# STM32F051x8 register map
File version: 1.0
Registers are 32-bit, read-write, reset 0x0 unless marked. A register's access mark holds for its fields unless they carry their own. Offsets are from the block's base; [hi:lo] are bit positions; {n}, {i} and the like mark numbered series.

## COMP12_COMMON
Base 0x4001001C; alternate view of COMP
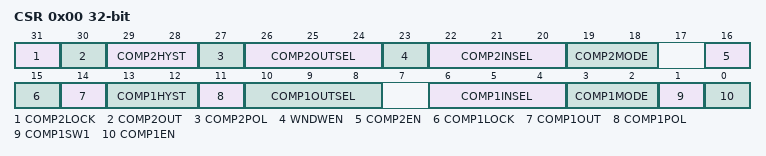
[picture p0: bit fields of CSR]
0x00 CSR — COMP control and status register, used for bits common to several COMP instances
  [31] COMP2LOCK
  [30] COMP2OUT — COMP2 output level
  [29:28] COMP2HYST — COMP2 hysteresis
  [27] COMP2POL — COMP2 output polarity
  [26:24] COMP2OUTSEL — COMP2 output select
  [23] WNDWEN — COMPx window mode. Bit intended to be used with COMP common instance (COMP_Common_TypeDef)
    0=DISABLE (Window mode disable: Comparators 1 and 2 are independent); 1=COMP1_INPUT_PLUS_COMMON (Window mode enable: Comparators instances pair COMP1 and COMP2 have their input plus connected together. The common input is COMP1 input plus (COMP2 input plus is no more accessible).)
  [22:20] COMP2INSEL — COMP2 inverting input select
  [19:18] COMP2MODE — COMP2 power mode
  [16] COMP2EN — COMP2 enable
  [15] COMP1LOCK
  [14] COMP1OUT — COMP1 output level
  [13:12] COMP1HYST — COMP1 hysteresis
    0=NONE (No hysteresis); 1=LOW (Hysteresis level low); 2=MEDIUM (Hysteresis level medium); 3=HIGH (Hysteresis level high)
  [11] COMP1POL — COMP1 output polarity
    0=NONINVERTED (COMP output polarity is not inverted: comparator output is high when the plus (non-inverting) input is at a higher voltage than the minus (inverting) input); 1=INVERTED (COMP output polarity is inverted: comparator output is low when the plus (non-inverting) input is at a lower voltage than the minus (inverting) input)
  [10:8] COMP1OUTSEL — COMP1 output select
    0=NONE (COMP output is not connected to other peripherals (except GPIO and EXTI that are always connected to COMP output)); 1=TIM1_BKIN (COMP output connected to TIM1 break input (BKIN)); 2=TIM1_IC1 (COMP output connected to TIM1 input capture 1); 3=TIM1_OCCLR (COMP output connected to TIM1 OCREF clear); 4=TIM2_IC4 (COMP output connected to TIM2 input capture 4); 5=TIM2_OCCLR (COMP output connected to TIM2 OCREF clear); 6=TIM3_IC1 (COMP output connected to TIM3 input capture 1); 7=TIM3_OCCLR (COMP output connected to TIM3 OCREF clear)
  [6:4] COMP1INSEL — COMP1 inverting input select
    0=MINUS_1_4VREFINT (Comparator input minus connected to 1/4 VrefInt); 1=MINUS_1_2VREFINT (Comparator input minus connected to 1/2 VrefInt); 2=MINUS_3_4VREFINT (Comparator input minus connected to 3/4 VrefInt); 3=VREFINT (Comparator input minus connected to VrefInt); 4=DAC1_CH1 (Comparator input minus connected to DAC1 channel 1 (DAC_OUT1)); 5=DAC1_CH2 (Comparator input minus connected to DAC1 channel 2 (DAC_OUT2)); 6=IO1 (Comparator input minus connected to IO1 (pin PA0 for COMP1, pin PA2 for COMP2))
  [3:2] COMP1MODE — COMP1 power mode
    0=HIGHSPEED (COMP power mode to high speed); 1=MEDIUMSPEED (COMP power mode to medium speed); 2=LOWPOWER (COMP power mode to low power); 3=ULTRALOWPOWER (COMP power mode to ultra-low power)
  [1] COMP1SW1 — COMP1 SW1 switch control
    0=IO1 (Comparator input plus connected to IO1 (pin PA1 for COMP1, pin PA3 for COMP2)); 1=DAC1_CH1 (Comparator input plus connected to DAC1 channel 1 (DAC_OUT1), through dedicated switch (Note: this switch is solely intended to redirect signals onto high impedance input, such as COMP1 input plus (highly resistive switch)) (specific to COMP instance: COMP1))
  [0] COMP1EN — COMP1 enable

## EXTI — External Interrupt/Event Controller
Base 0x40010400
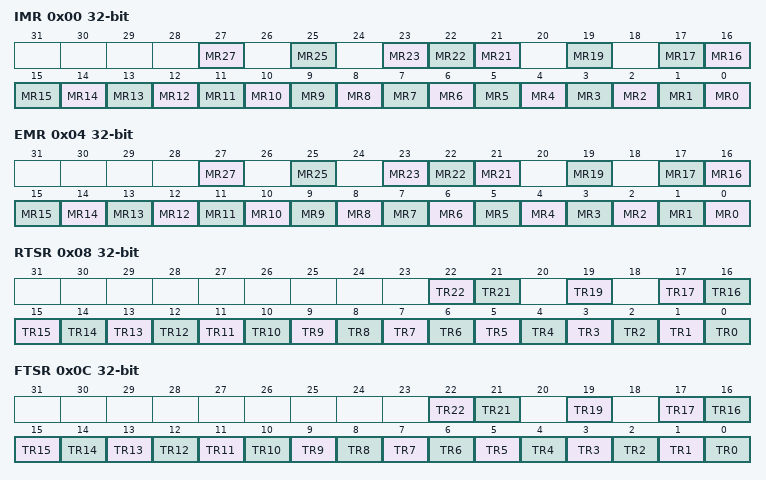
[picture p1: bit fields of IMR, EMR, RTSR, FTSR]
0x00 IMR — EXTI Interrupt mask register
  [27] MR27 — Interrupt Mask on line 27
  [25] MR25 — Interrupt Mask on line 25
  [23] MR23 — Interrupt Mask on line 23
  [22] MR22 — Interrupt Mask on line 22
  [21] MR21 — Interrupt Mask on line 21
  [19] MR19 — Interrupt Mask on line 19
  [n] MR{n} (n=0..17) — Interrupt Mask on line {n}
0x04 EMR — EXTI Event mask register
  [27] MR27 — Event Mask on line 27
  [25] MR25 — Event Mask on line 25
  [23] MR23 — Event Mask on line 23
  [22] MR22 — Event Mask on line 22
  [21] MR21 — Event Mask on line 21
  [19] MR19 — Event Mask on line 19
  [n] MR{n} (n=0..17) — Event Mask on line {n}
0x08 RTSR — EXTI Rising trigger selection register
  [22] TR22 — Rising trigger event configuration bit of line 22
  [21] TR21 — Rising trigger event configuration bit of line 21
  [19] TR19 — Rising trigger event configuration bit of line 19
  [n] TR{n} (n=0..17) — Rising trigger event configuration bit of line {n}
0x0C FTSR — EXTI Falling trigger selection register
  [22] TR22 — Falling trigger event configuration bit of line 22
  [21] TR21 — Falling trigger event configuration bit of line 21
  [19] TR19 — Falling trigger event configuration bit of line 19
  [n] TR{n} (n=0..17) — Falling trigger event configuration bit of line {n}
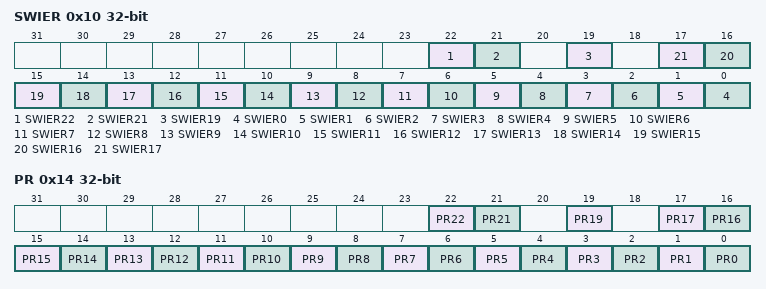
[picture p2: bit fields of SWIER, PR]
0x10 SWIER — EXTI Software interrupt event register
  [22] SWIER22 — Software Interrupt on line 22
  [21] SWIER21 — Software Interrupt on line 21
  [19] SWIER19 — Software Interrupt on line 19
  [n] SWIER{n} (n=0..17) — Software Interrupt on line {n}
0x14 PR — EXTI Pending register
  [22] PR22 — Pending bit 22
  [21] PR21 — Pending bit 21
  [19] PR19 — Pending bit 19
  [n] PR{n} (n=0..17) — Pending bit {n}
